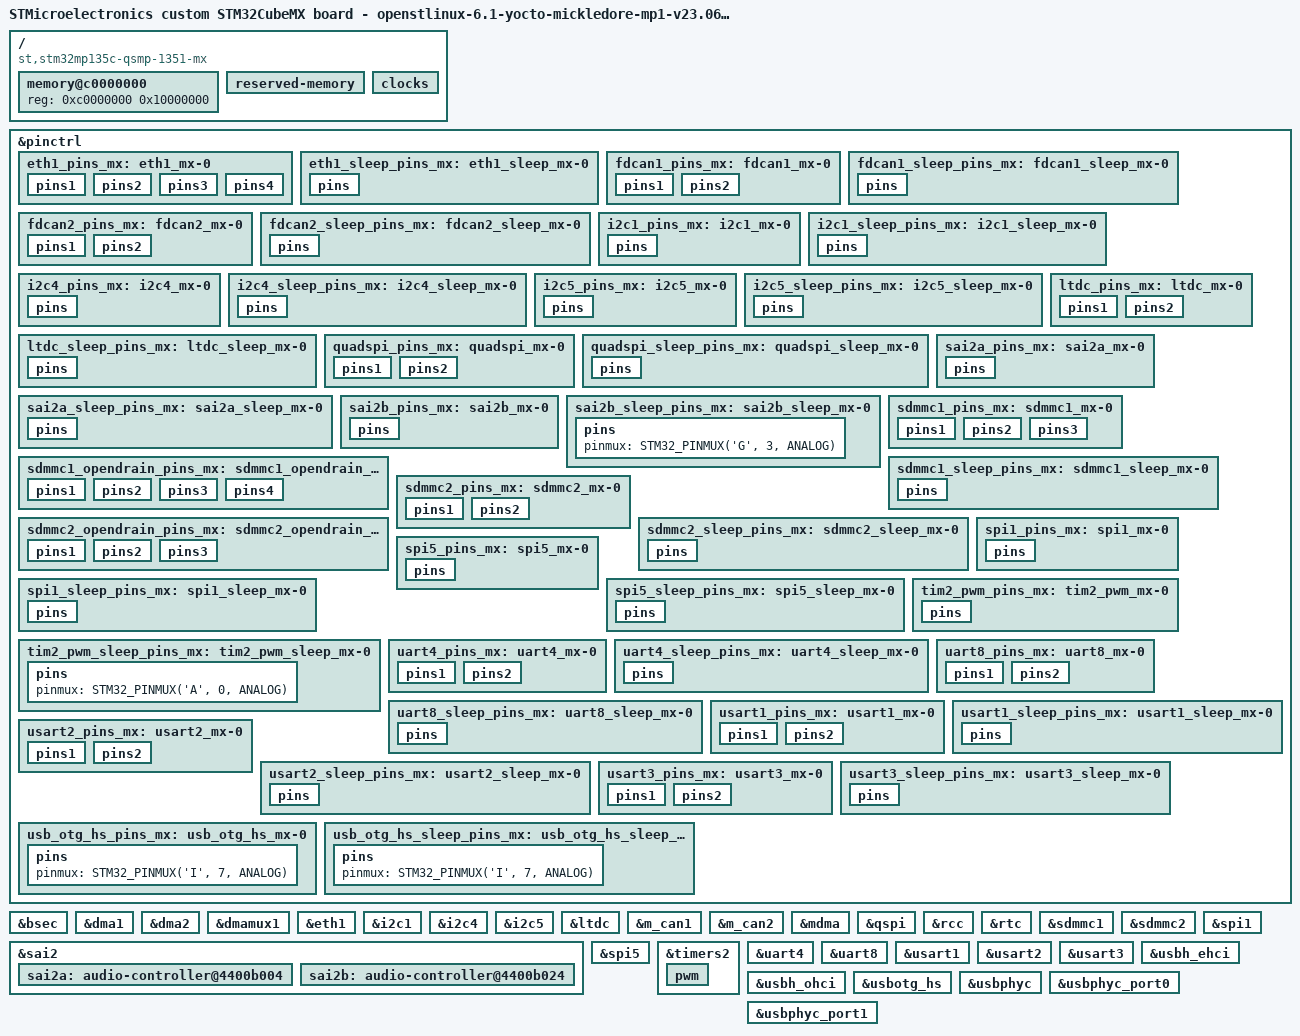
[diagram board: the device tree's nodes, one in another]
// SPDX-License-Identifier: (GPL-2.0-or-later OR BSD-3-Clause)
/*
 * Copyright (C) 2024, STMicroelectronics - All Rights Reserved
 * Author: STM32CubeMX code generation for STMicroelectronics.
 */

/* For more information on Device Tree configuration, please refer to
 * https://wiki.st.com/stm32mpu/wiki/Category:Device_tree_configuration
 */

/dts-v1/;
#include <dt-bindings/pinctrl/stm32-pinfunc.h>

#include "stm32mp135.dtsi"
#include "stm32mp13xc.dtsi"

/* USER CODE BEGIN includes */
/* USER CODE END includes */

/ {
	model = "STMicroelectronics custom STM32CubeMX board - openstlinux-6.1-yocto-mickledore-mp1-v23.06.21";
	compatible = "st,stm32mp135c-qsmp-1351-mx", "st,stm32mp135";

	memory@c0000000 {
		device_type = "memory";
		reg = <0xc0000000 0x10000000>;

		/* USER CODE BEGIN memory */
		/* USER CODE END memory */
	};

	reserved-memory {
		#address-cells = <1>;
		#size-cells = <1>;
		ranges;

		/* USER CODE BEGIN reserved-memory */
		/* USER CODE END reserved-memory */
	};

	/* USER CODE BEGIN root */
	/* USER CODE END root */

	clocks{

		/* USER CODE BEGIN clocks */
		/* USER CODE END clocks */
	};

}; /*root*/

&pinctrl {

	eth1_pins_mx: eth1_mx-0 {
		pins1 {
			pinmux = <STM32_PINMUX('A', 2, AF11)>; /* ETH1_MDIO */
			bias-disable;
			drive-push-pull;
			slew-rate = <0>;
		};
		pins2 {
			pinmux = <STM32_PINMUX('A', 7, AF11)>, /* ETH1_RX_CTL */
					 <STM32_PINMUX('B', 0, AF11)>, /* ETH1_RXD2 */
					 <STM32_PINMUX('B', 1, AF11)>, /* ETH1_RXD3 */
					 <STM32_PINMUX('C', 4, AF11)>, /* ETH1_RXD0 */
					 <STM32_PINMUX('C', 5, AF11)>, /* ETH1_RXD1 */
					 <STM32_PINMUX('D', 7, AF10)>; /* ETH1_RX_CLK */
			bias-disable;
		};
		pins3 {
			pinmux = <STM32_PINMUX('B', 11, AF11)>, /* ETH1_TX_CTL */
					 <STM32_PINMUX('C', 1, AF11)>, /* ETH1_GTX_CLK */
					 <STM32_PINMUX('C', 2, AF11)>, /* ETH1_TXD2 */
					 <STM32_PINMUX('E', 5, AF10)>, /* ETH1_TXD3 */
					 <STM32_PINMUX('F', 12, AF11)>, /* ETH1_CLK125 */
					 <STM32_PINMUX('G', 2, AF11)>, /* ETH1_MDC */
					 <STM32_PINMUX('G', 13, AF11)>, /* ETH1_TXD0 */
					 <STM32_PINMUX('G', 14, AF11)>; /* ETH1_TXD1 */
			bias-disable;
			drive-push-pull;
			slew-rate = <2>;
		};
		pins4 {
			pinmux = <STM32_PINMUX('H', 6, AF10)>; /* ETH1_PHY_INTN */
			bias-pull-up;
		};
	};

	eth1_sleep_pins_mx: eth1_sleep_mx-0 {
		pins {
			pinmux = <STM32_PINMUX('A', 2, ANALOG)>, /* ETH1_MDIO */
					 <STM32_PINMUX('A', 7, ANALOG)>, /* ETH1_RX_CTL */
					 <STM32_PINMUX('B', 0, ANALOG)>, /* ETH1_RXD2 */
					 <STM32_PINMUX('B', 1, ANALOG)>, /* ETH1_RXD3 */
					 <STM32_PINMUX('B', 11, ANALOG)>, /* ETH1_TX_CTL */
					 <STM32_PINMUX('C', 1, ANALOG)>, /* ETH1_GTX_CLK */
					 <STM32_PINMUX('C', 2, ANALOG)>, /* ETH1_TXD2 */
					 <STM32_PINMUX('C', 4, ANALOG)>, /* ETH1_RXD0 */
					 <STM32_PINMUX('C', 5, ANALOG)>, /* ETH1_RXD1 */
					 <STM32_PINMUX('D', 7, ANALOG)>, /* ETH1_RX_CLK */
					 <STM32_PINMUX('E', 5, ANALOG)>, /* ETH1_TXD3 */
					 <STM32_PINMUX('F', 12, ANALOG)>, /* ETH1_CLK125 */
					 <STM32_PINMUX('G', 2, ANALOG)>, /* ETH1_MDC */
					 <STM32_PINMUX('G', 13, ANALOG)>, /* ETH1_TXD0 */
					 <STM32_PINMUX('G', 14, ANALOG)>, /* ETH1_TXD1 */
					 <STM32_PINMUX('H', 6, ANALOG)>; /* ETH1_PHY_INTN */
		};
	};

	fdcan1_pins_mx: fdcan1_mx-0 {
		pins1 {
			pinmux = <STM32_PINMUX('D', 0, AF9)>; /* FDCAN1_RX */
			bias-disable;
		};
		pins2 {
			pinmux = <STM32_PINMUX('E', 10, AF9)>; /* FDCAN1_TX */
			bias-disable;
			drive-push-pull;
			slew-rate = <0>;
		};
	};

	fdcan1_sleep_pins_mx: fdcan1_sleep_mx-0 {
		pins {
			pinmux = <STM32_PINMUX('D', 0, ANALOG)>, /* FDCAN1_RX */
					 <STM32_PINMUX('E', 10, ANALOG)>; /* FDCAN1_TX */
		};
	};

	fdcan2_pins_mx: fdcan2_mx-0 {
		pins1 {
			pinmux = <STM32_PINMUX('B', 13, AF9)>; /* FDCAN2_TX */
			bias-disable;
			drive-push-pull;
			slew-rate = <0>;
		};
		pins2 {
			pinmux = <STM32_PINMUX('E', 0, AF9)>; /* FDCAN2_RX */
			bias-disable;
		};
	};

	fdcan2_sleep_pins_mx: fdcan2_sleep_mx-0 {
		pins {
			pinmux = <STM32_PINMUX('B', 13, ANALOG)>, /* FDCAN2_TX */
					 <STM32_PINMUX('E', 0, ANALOG)>; /* FDCAN2_RX */
		};
	};

	i2c1_pins_mx: i2c1_mx-0 {
		pins {
			pinmux = <STM32_PINMUX('D', 12, AF5)>, /* I2C1_SCL */
					 <STM32_PINMUX('E', 8, AF5)>; /* I2C1_SDA */
			bias-disable;
			drive-open-drain;
			slew-rate = <0>;
		};
	};

	i2c1_sleep_pins_mx: i2c1_sleep_mx-0 {
		pins {
			pinmux = <STM32_PINMUX('D', 12, ANALOG)>, /* I2C1_SCL */
					 <STM32_PINMUX('E', 8, ANALOG)>; /* I2C1_SDA */
		};
	};

	i2c4_pins_mx: i2c4_mx-0 {
		pins {
			pinmux = <STM32_PINMUX('B', 7, AF6)>, /* I2C4_SDA */
					 <STM32_PINMUX('E', 2, AF4)>; /* I2C4_SCL */
			bias-disable;
			drive-open-drain;
			slew-rate = <0>;
		};
	};

	i2c4_sleep_pins_mx: i2c4_sleep_mx-0 {
		pins {
			pinmux = <STM32_PINMUX('B', 7, ANALOG)>, /* I2C4_SDA */
					 <STM32_PINMUX('E', 2, ANALOG)>; /* I2C4_SCL */
		};
	};

	i2c5_pins_mx: i2c5_mx-0 {
		pins {
			pinmux = <STM32_PINMUX('D', 1, AF4)>, /* I2C5_SCL */
					 <STM32_PINMUX('E', 13, AF4)>; /* I2C5_SDA */
			bias-disable;
			drive-open-drain;
			slew-rate = <0>;
		};
	};

	i2c5_sleep_pins_mx: i2c5_sleep_mx-0 {
		pins {
			pinmux = <STM32_PINMUX('D', 1, ANALOG)>, /* I2C5_SCL */
					 <STM32_PINMUX('E', 13, ANALOG)>; /* I2C5_SDA */
		};
	};

	ltdc_pins_mx: ltdc_mx-0 {
		pins1 {
			pinmux = <STM32_PINMUX('A', 9, AF14)>, /* LTDC_R6 */
					 <STM32_PINMUX('A', 15, AF11)>, /* LTDC_G7 */
					 <STM32_PINMUX('B', 5, AF14)>, /* LTDC_DE */
					 <STM32_PINMUX('B', 6, AF7)>, /* LTDC_B6 */
					 <STM32_PINMUX('B', 10, AF14)>, /* LTDC_R3 */
					 <STM32_PINMUX('B', 12, AF14)>, /* LTDC_VSYNC */
					 <STM32_PINMUX('D', 5, AF13)>, /* LTDC_B0 */
					 <STM32_PINMUX('D', 10, AF14)>, /* LTDC_B2 */
					 <STM32_PINMUX('D', 11, AF11)>, /* LTDC_R7 */
					 <STM32_PINMUX('D', 14, AF14)>, /* LTDC_R4 */
					 <STM32_PINMUX('D', 15, AF14)>, /* LTDC_B5 */
					 <STM32_PINMUX('E', 7, AF14)>, /* LTDC_R5 */
					 <STM32_PINMUX('E', 11, AF9)>, /* LTDC_R0 */
					 <STM32_PINMUX('E', 12, AF14)>, /* LTDC_G6 */
					 <STM32_PINMUX('E', 15, AF14)>, /* LTDC_B7 */
					 <STM32_PINMUX('F', 1, AF14)>, /* LTDC_G1 */
					 <STM32_PINMUX('F', 2, AF14)>, /* LTDC_B3 */
					 <STM32_PINMUX('F', 3, AF14)>, /* LTDC_G3 */
					 <STM32_PINMUX('F', 5, AF9)>, /* LTDC_G0 */
					 <STM32_PINMUX('G', 0, AF14)>, /* LTDC_G5 */
					 <STM32_PINMUX('G', 5, AF11)>, /* LTDC_G4 */
					 <STM32_PINMUX('G', 7, AF11)>, /* LTDC_R1 */
					 <STM32_PINMUX('G', 8, AF7)>, /* LTDC_B1 */
					 <STM32_PINMUX('H', 8, AF14)>, /* LTDC_R2 */
					 <STM32_PINMUX('H', 10, AF13)>, /* LTDC_HSYNC */
					 <STM32_PINMUX('H', 13, AF14)>, /* LTDC_G2 */
					 <STM32_PINMUX('H', 14, AF11)>; /* LTDC_B4 */
			bias-disable;
			drive-push-pull;
			slew-rate = <0>;
		};
		pins2 {
			pinmux = <STM32_PINMUX('D', 9, AF13)>; /* LTDC_CLK */
			bias-disable;
			drive-push-pull;
			slew-rate = <1>;
		};
	};

	ltdc_sleep_pins_mx: ltdc_sleep_mx-0 {
		pins {
			pinmux = <STM32_PINMUX('A', 9, ANALOG)>, /* LTDC_R6 */
					 <STM32_PINMUX('A', 15, ANALOG)>, /* LTDC_G7 */
					 <STM32_PINMUX('B', 5, ANALOG)>, /* LTDC_DE */
					 <STM32_PINMUX('B', 6, ANALOG)>, /* LTDC_B6 */
					 <STM32_PINMUX('B', 10, ANALOG)>, /* LTDC_R3 */
					 <STM32_PINMUX('B', 12, ANALOG)>, /* LTDC_VSYNC */
					 <STM32_PINMUX('D', 5, ANALOG)>, /* LTDC_B0 */
					 <STM32_PINMUX('D', 9, ANALOG)>, /* LTDC_CLK */
					 <STM32_PINMUX('D', 10, ANALOG)>, /* LTDC_B2 */
					 <STM32_PINMUX('D', 11, ANALOG)>, /* LTDC_R7 */
					 <STM32_PINMUX('D', 14, ANALOG)>, /* LTDC_R4 */
					 <STM32_PINMUX('D', 15, ANALOG)>, /* LTDC_B5 */
					 <STM32_PINMUX('E', 7, ANALOG)>, /* LTDC_R5 */
					 <STM32_PINMUX('E', 11, ANALOG)>, /* LTDC_R0 */
					 <STM32_PINMUX('E', 12, ANALOG)>, /* LTDC_G6 */
					 <STM32_PINMUX('E', 15, ANALOG)>, /* LTDC_B7 */
					 <STM32_PINMUX('F', 1, ANALOG)>, /* LTDC_G1 */
					 <STM32_PINMUX('F', 2, ANALOG)>, /* LTDC_B3 */
					 <STM32_PINMUX('F', 3, ANALOG)>, /* LTDC_G3 */
					 <STM32_PINMUX('F', 5, ANALOG)>, /* LTDC_G0 */
					 <STM32_PINMUX('G', 0, ANALOG)>, /* LTDC_G5 */
					 <STM32_PINMUX('G', 5, ANALOG)>, /* LTDC_G4 */
					 <STM32_PINMUX('G', 7, ANALOG)>, /* LTDC_R1 */
					 <STM32_PINMUX('G', 8, ANALOG)>, /* LTDC_B1 */
					 <STM32_PINMUX('H', 8, ANALOG)>, /* LTDC_R2 */
					 <STM32_PINMUX('H', 10, ANALOG)>, /* LTDC_HSYNC */
					 <STM32_PINMUX('H', 13, ANALOG)>, /* LTDC_G2 */
					 <STM32_PINMUX('H', 14, ANALOG)>; /* LTDC_B4 */
		};
	};

	quadspi_pins_mx: quadspi_mx-0 {
		pins1 {
			pinmux = <STM32_PINMUX('B', 2, AF9)>, /* QUADSPI_BK1_NCS */
					 <STM32_PINMUX('E', 9, AF9)>, /* QUADSPI_BK1_IO1 */
					 <STM32_PINMUX('F', 8, AF10)>; /* QUADSPI_BK1_IO0 */
			bias-disable;
			drive-push-pull;
			slew-rate = <1>;
		};
		pins2 {
			pinmux = <STM32_PINMUX('F', 10, AF9)>; /* QUADSPI_CLK */
			bias-disable;
			drive-push-pull;
			slew-rate = <2>;
		};
	};

	quadspi_sleep_pins_mx: quadspi_sleep_mx-0 {
		pins {
			pinmux = <STM32_PINMUX('B', 2, ANALOG)>, /* QUADSPI_BK1_NCS */
					 <STM32_PINMUX('E', 9, ANALOG)>, /* QUADSPI_BK1_IO1 */
					 <STM32_PINMUX('F', 8, ANALOG)>, /* QUADSPI_BK1_IO0 */
					 <STM32_PINMUX('F', 10, ANALOG)>; /* QUADSPI_CLK */
		};
	};

	sai2a_pins_mx: sai2a_mx-0 {
		pins {
			pinmux = <STM32_PINMUX('G', 1, AF3)>, /* SAI2_FS_A */
					 <STM32_PINMUX('G', 12, AF4)>, /* SAI2_SCK_A */
					 <STM32_PINMUX('H', 11, AF3)>; /* SAI2_SD_A */
			bias-disable;
			drive-push-pull;
			slew-rate = <0>;
		};
	};

	sai2a_sleep_pins_mx: sai2a_sleep_mx-0 {
		pins {
			pinmux = <STM32_PINMUX('G', 1, ANALOG)>, /* SAI2_FS_A */
					 <STM32_PINMUX('G', 12, ANALOG)>, /* SAI2_SCK_A */
					 <STM32_PINMUX('H', 11, ANALOG)>; /* SAI2_SD_A */
		};
	};

	sai2b_pins_mx: sai2b_mx-0 {
		pins {
			pinmux = <STM32_PINMUX('G', 3, AF6)>; /* SAI2_SD_B */
			bias-disable;
			drive-push-pull;
			slew-rate = <0>;
		};
	};

	sai2b_sleep_pins_mx: sai2b_sleep_mx-0 {
		pins {
			pinmux = <STM32_PINMUX('G', 3, ANALOG)>; /* SAI2_SD_B */
		};
	};

	sdmmc1_pins_mx: sdmmc1_mx-0 {
		pins1 {
			pinmux = <STM32_PINMUX('C', 9, AF12)>, /* SDMMC1_D1 */
					 <STM32_PINMUX('C', 10, AF12)>, /* SDMMC1_D2 */
					 <STM32_PINMUX('C', 11, AF12)>; /* SDMMC1_D3 */
			bias-disable;
			drive-push-pull;
			slew-rate = <1>;
		};
		pins2 {
			pinmux = <STM32_PINMUX('C', 12, AF12)>; /* SDMMC1_CK */
			bias-disable;
			drive-push-pull;
			slew-rate = <3>;
		};
		pins3 {
			pinmux = <STM32_PINMUX('C', 8, AF12)>, /* SDMMC1_D0 */
					 <STM32_PINMUX('D', 2, AF12)>; /* SDMMC1_CMD */
			bias-pull-up;
			drive-push-pull;
			slew-rate = <1>;
		};
	};

	sdmmc1_opendrain_pins_mx: sdmmc1_opendrain_mx-0 {
		pins1 {
			pinmux = <STM32_PINMUX('C', 9, AF12)>, /* SDMMC1_D1 */
					 <STM32_PINMUX('C', 10, AF12)>, /* SDMMC1_D2 */
					 <STM32_PINMUX('C', 11, AF12)>; /* SDMMC1_D3 */
			bias-disable;
			drive-push-pull;
			slew-rate = <1>;
		};
		pins2 {
			pinmux = <STM32_PINMUX('C', 12, AF12)>; /* SDMMC1_CK */
			bias-disable;
			drive-push-pull;
			slew-rate = <3>;
		};
		pins3 {
			pinmux = <STM32_PINMUX('C', 8, AF12)>; /* SDMMC1_D0 */
			bias-pull-up;
			drive-push-pull;
			slew-rate = <1>;
		};
		pins4 {
			pinmux = <STM32_PINMUX('D', 2, AF12)>; /* SDMMC1_CMD */
			bias-pull-up;
			drive-open-drain;
			slew-rate = <1>;
		};
	};

	sdmmc1_sleep_pins_mx: sdmmc1_sleep_mx-0 {
		pins {
			pinmux = <STM32_PINMUX('C', 8, ANALOG)>, /* SDMMC1_D0 */
					 <STM32_PINMUX('C', 9, ANALOG)>, /* SDMMC1_D1 */
					 <STM32_PINMUX('C', 10, ANALOG)>, /* SDMMC1_D2 */
					 <STM32_PINMUX('C', 11, ANALOG)>, /* SDMMC1_D3 */
					 <STM32_PINMUX('C', 12, ANALOG)>, /* SDMMC1_CK */
					 <STM32_PINMUX('D', 2, ANALOG)>; /* SDMMC1_CMD */
		};
	};

	sdmmc2_pins_mx: sdmmc2_mx-0 {
		pins1 {
			pinmux = <STM32_PINMUX('B', 3, AF10)>, /* SDMMC2_D2 */
					 <STM32_PINMUX('B', 4, AF10)>, /* SDMMC2_D3 */
					 <STM32_PINMUX('B', 9, AF10)>, /* SDMMC2_D5 */
					 <STM32_PINMUX('B', 14, AF10)>, /* SDMMC2_D0 */
					 <STM32_PINMUX('B', 15, AF10)>, /* SDMMC2_D1 */
					 <STM32_PINMUX('C', 6, AF10)>, /* SDMMC2_D6 */
					 <STM32_PINMUX('C', 7, AF10)>, /* SDMMC2_D7 */
					 <STM32_PINMUX('F', 0, AF10)>, /* SDMMC2_D4 */
					 <STM32_PINMUX('G', 6, AF10)>; /* SDMMC2_CMD */
			bias-disable;
			drive-push-pull;
			slew-rate = <1>;
		};
		pins2 {
			pinmux = <STM32_PINMUX('E', 3, AF10)>; /* SDMMC2_CK */
			bias-disable;
			drive-push-pull;
			slew-rate = <3>;
		};
	};

	sdmmc2_opendrain_pins_mx: sdmmc2_opendrain_mx-0 {
		pins1 {
			pinmux = <STM32_PINMUX('B', 3, AF10)>, /* SDMMC2_D2 */
					 <STM32_PINMUX('B', 4, AF10)>, /* SDMMC2_D3 */
					 <STM32_PINMUX('B', 9, AF10)>, /* SDMMC2_D5 */
					 <STM32_PINMUX('B', 14, AF10)>, /* SDMMC2_D0 */
					 <STM32_PINMUX('B', 15, AF10)>, /* SDMMC2_D1 */
					 <STM32_PINMUX('C', 6, AF10)>, /* SDMMC2_D6 */
					 <STM32_PINMUX('C', 7, AF10)>, /* SDMMC2_D7 */
					 <STM32_PINMUX('F', 0, AF10)>; /* SDMMC2_D4 */
			bias-disable;
			drive-push-pull;
			slew-rate = <1>;
		};
		pins2 {
			pinmux = <STM32_PINMUX('E', 3, AF10)>; /* SDMMC2_CK */
			bias-disable;
			drive-push-pull;
			slew-rate = <3>;
		};
		pins3 {
			pinmux = <STM32_PINMUX('G', 6, AF10)>; /* SDMMC2_CMD */
			bias-disable;
			drive-open-drain;
			slew-rate = <1>;
		};
	};

	sdmmc2_sleep_pins_mx: sdmmc2_sleep_mx-0 {
		pins {
			pinmux = <STM32_PINMUX('B', 3, ANALOG)>, /* SDMMC2_D2 */
					 <STM32_PINMUX('B', 4, ANALOG)>, /* SDMMC2_D3 */
					 <STM32_PINMUX('B', 9, ANALOG)>, /* SDMMC2_D5 */
					 <STM32_PINMUX('B', 14, ANALOG)>, /* SDMMC2_D0 */
					 <STM32_PINMUX('B', 15, ANALOG)>, /* SDMMC2_D1 */
					 <STM32_PINMUX('C', 6, ANALOG)>, /* SDMMC2_D6 */
					 <STM32_PINMUX('C', 7, ANALOG)>, /* SDMMC2_D7 */
					 <STM32_PINMUX('E', 3, ANALOG)>, /* SDMMC2_CK */
					 <STM32_PINMUX('F', 0, ANALOG)>, /* SDMMC2_D4 */
					 <STM32_PINMUX('G', 6, ANALOG)>; /* SDMMC2_CMD */
		};
	};

	spi1_pins_mx: spi1_mx-0 {
		pins {
			pinmux = <STM32_PINMUX('A', 3, AF5)>, /* SPI1_MOSI */
					 <STM32_PINMUX('A', 5, AF5)>, /* SPI1_NSS */
					 <STM32_PINMUX('A', 6, AF5)>, /* SPI1_MISO */
					 <STM32_PINMUX('C', 3, AF6)>; /* SPI1_SCK */
			bias-disable;
			drive-push-pull;
			slew-rate = <1>;
		};
	};

	spi1_sleep_pins_mx: spi1_sleep_mx-0 {
		pins {
			pinmux = <STM32_PINMUX('A', 3, ANALOG)>, /* SPI1_MOSI */
					 <STM32_PINMUX('A', 5, ANALOG)>, /* SPI1_NSS */
					 <STM32_PINMUX('A', 6, ANALOG)>, /* SPI1_MISO */
					 <STM32_PINMUX('C', 3, ANALOG)>; /* SPI1_SCK */
		};
	};

	spi5_pins_mx: spi5_mx-0 {
		pins {
			pinmux = <STM32_PINMUX('E', 4, AF1)>, /* SPI5_MISO */
					 <STM32_PINMUX('F', 6, AF5)>, /* SPI5_NSS */
					 <STM32_PINMUX('G', 10, AF5)>, /* SPI5_SCK */
					 <STM32_PINMUX('H', 12, AF5)>; /* SPI5_MOSI */
			bias-disable;
			drive-push-pull;
			slew-rate = <1>;
		};
	};

	spi5_sleep_pins_mx: spi5_sleep_mx-0 {
		pins {
			pinmux = <STM32_PINMUX('E', 4, ANALOG)>, /* SPI5_MISO */
					 <STM32_PINMUX('F', 6, ANALOG)>, /* SPI5_NSS */
					 <STM32_PINMUX('G', 10, ANALOG)>, /* SPI5_SCK */
					 <STM32_PINMUX('H', 12, ANALOG)>; /* SPI5_MOSI */
		};
	};

	tim2_pwm_pins_mx: tim2_pwm_mx-0 {
		pins {
			pinmux = <STM32_PINMUX('A', 0, AF1)>; /* TIM2_CH1 */
			bias-disable;
			drive-push-pull;
			slew-rate = <0>;
		};
	};

	tim2_pwm_sleep_pins_mx: tim2_pwm_sleep_mx-0 {
		pins {
			pinmux = <STM32_PINMUX('A', 0, ANALOG)>; /* TIM2_CH1 */
		};
	};

	uart4_pins_mx: uart4_mx-0 {
		pins1 {
			pinmux = <STM32_PINMUX('D', 6, AF8)>; /* UART4_TX */
			bias-disable;
			drive-push-pull;
			slew-rate = <0>;
		};
		pins2 {
			pinmux = <STM32_PINMUX('D', 8, AF8)>; /* UART4_RX */
			bias-disable;
		};
	};

	uart4_sleep_pins_mx: uart4_sleep_mx-0 {
		pins {
			pinmux = <STM32_PINMUX('D', 6, ANALOG)>, /* UART4_TX */
					 <STM32_PINMUX('D', 8, ANALOG)>; /* UART4_RX */
		};
	};

	uart8_pins_mx: uart8_mx-0 {
		pins1 {
			pinmux = <STM32_PINMUX('E', 1, AF8)>, /* UART8_TX */
					 <STM32_PINMUX('E', 14, AF8)>; /* UART8_DE */
			bias-disable;
			drive-push-pull;
			slew-rate = <0>;
		};
		pins2 {
			pinmux = <STM32_PINMUX('F', 9, AF8)>; /* UART8_RX */
			bias-disable;
		};
	};

	uart8_sleep_pins_mx: uart8_sleep_mx-0 {
		pins {
			pinmux = <STM32_PINMUX('E', 1, ANALOG)>, /* UART8_TX */
					 <STM32_PINMUX('E', 14, ANALOG)>, /* UART8_DE */
					 <STM32_PINMUX('F', 9, ANALOG)>; /* UART8_RX */
		};
	};

	usart1_pins_mx: usart1_mx-0 {
		pins1 {
			pinmux = <STM32_PINMUX('A', 12, AF7)>, /* USART1_DE */
					 <STM32_PINMUX('C', 0, AF7)>; /* USART1_TX */
			bias-disable;
			drive-push-pull;
			slew-rate = <0>;
		};
		pins2 {
			pinmux = <STM32_PINMUX('D', 13, AF7)>; /* USART1_RX */
			bias-disable;
		};
	};

	usart1_sleep_pins_mx: usart1_sleep_mx-0 {
		pins {
			pinmux = <STM32_PINMUX('A', 12, ANALOG)>, /* USART1_DE */
					 <STM32_PINMUX('C', 0, ANALOG)>, /* USART1_TX */
					 <STM32_PINMUX('D', 13, ANALOG)>; /* USART1_RX */
		};
	};

	usart2_pins_mx: usart2_mx-0 {
		pins1 {
			pinmux = <STM32_PINMUX('D', 3, AF3)>, /* USART2_CTS */
					 <STM32_PINMUX('F', 4, AF3)>; /* USART2_RX */
			bias-disable;
		};
		pins2 {
			pinmux = <STM32_PINMUX('D', 4, AF3)>, /* USART2_RTS */
					 <STM32_PINMUX('F', 13, AF7)>; /* USART2_TX */
			bias-disable;
			drive-push-pull;
			slew-rate = <0>;
		};
	};

	usart2_sleep_pins_mx: usart2_sleep_mx-0 {
		pins {
			pinmux = <STM32_PINMUX('D', 3, ANALOG)>, /* USART2_CTS */
					 <STM32_PINMUX('D', 4, ANALOG)>, /* USART2_RTS */
					 <STM32_PINMUX('F', 4, ANALOG)>, /* USART2_RX */
					 <STM32_PINMUX('F', 13, ANALOG)>; /* USART2_TX */
		};
	};

	usart3_pins_mx: usart3_mx-0 {
		pins1 {
			pinmux = <STM32_PINMUX('G', 11, AF7)>; /* USART3_TX */
			bias-disable;
			drive-push-pull;
			slew-rate = <0>;
		};
		pins2 {
			pinmux = <STM32_PINMUX('G', 4, AF8)>; /* USART3_RX */
			bias-disable;
		};
	};

	usart3_sleep_pins_mx: usart3_sleep_mx-0 {
		pins {
			pinmux = <STM32_PINMUX('G', 4, ANALOG)>, /* USART3_RX */
					 <STM32_PINMUX('G', 11, ANALOG)>; /* USART3_TX */
		};
	};

	usb_otg_hs_pins_mx: usb_otg_hs_mx-0 {
		pins {
			pinmux = <STM32_PINMUX('I', 7, ANALOG)>; /* USB_OTG_HS_VBUS */
		};
	};

	usb_otg_hs_sleep_pins_mx: usb_otg_hs_sleep_mx-0 {
		pins {
			pinmux = <STM32_PINMUX('I', 7, ANALOG)>; /* USB_OTG_HS_VBUS */
		};
	};

	/* USER CODE BEGIN pinctrl */
	/* USER CODE END pinctrl */
};

&bsec{
	status = "okay";

	/* USER CODE BEGIN bsec */
	/* USER CODE END bsec */
};

&dma1{
	status = "okay";

	/* USER CODE BEGIN dma1 */
	/* USER CODE END dma1 */
};

&dma2{
	status = "okay";

	/* USER CODE BEGIN dma2 */
	/* USER CODE END dma2 */
};

&dmamux1{
	status = "okay";

	dma-masters = <&dma1 &dma2>;
	dma-channels = <16>;

	/* USER CODE BEGIN dmamux1 */
	/* USER CODE END dmamux1 */
};

&eth1{
	pinctrl-names = "default", "sleep";
	pinctrl-0 = <&eth1_pins_mx>;
	pinctrl-1 = <&eth1_sleep_pins_mx>;
	status = "okay";

	/* USER CODE BEGIN eth1 */
	/* USER CODE END eth1 */
};

&i2c1{
	pinctrl-names = "default", "sleep";
	pinctrl-0 = <&i2c1_pins_mx>;
	pinctrl-1 = <&i2c1_sleep_pins_mx>;
	status = "okay";

	/* USER CODE BEGIN i2c1 */
	/* USER CODE END i2c1 */
};

&i2c4{
	pinctrl-names = "default", "sleep";
	pinctrl-0 = <&i2c4_pins_mx>;
	pinctrl-1 = <&i2c4_sleep_pins_mx>;
	status = "okay";

	/* USER CODE BEGIN i2c4 */
	/* USER CODE END i2c4 */
};

&i2c5{
	pinctrl-names = "default", "sleep";
	pinctrl-0 = <&i2c5_pins_mx>;
	pinctrl-1 = <&i2c5_sleep_pins_mx>;
	status = "okay";

	/* USER CODE BEGIN i2c5 */
	/* USER CODE END i2c5 */
};

&ltdc{
	pinctrl-names = "default", "sleep";
	pinctrl-0 = <&ltdc_pins_mx>;
	pinctrl-1 = <&ltdc_sleep_pins_mx>;
	status = "okay";

	/* USER CODE BEGIN ltdc */
	/* USER CODE END ltdc */
};

&m_can1{
	pinctrl-names = "default", "sleep";
	pinctrl-0 = <&fdcan1_pins_mx>;
	pinctrl-1 = <&fdcan1_sleep_pins_mx>;
	status = "okay";

	/* USER CODE BEGIN m_can1 */
	/* USER CODE END m_can1 */
};

&m_can2{
	pinctrl-names = "default", "sleep";
	pinctrl-0 = <&fdcan2_pins_mx>;
	pinctrl-1 = <&fdcan2_sleep_pins_mx>;
	status = "okay";

	/* USER CODE BEGIN m_can2 */
	/* USER CODE END m_can2 */
};

&mdma{
	status = "okay";

	/* USER CODE BEGIN mdma */
	/* USER CODE END mdma */
};

&qspi{
	pinctrl-names = "default", "sleep";
	pinctrl-0 = <&quadspi_pins_mx>;
	pinctrl-1 = <&quadspi_sleep_pins_mx>;
	status = "okay";

	/* USER CODE BEGIN qspi */
	/* USER CODE END qspi */
};

&rcc{
	status = "okay";

	/* USER CODE BEGIN rcc */
	/* USER CODE END rcc */
};

&rtc{
	status = "okay";

	/* USER CODE BEGIN rtc */
	/* USER CODE END rtc */
};

&sai2{
	pinctrl-names = "default", "sleep";
	pinctrl-0 = <&sai2a_pins_mx>, <&sai2b_pins_mx>;
	pinctrl-1 = <&sai2a_sleep_pins_mx>, <&sai2b_sleep_pins_mx>;
	status = "okay";

	/* USER CODE BEGIN sai2 */
	/* USER CODE END sai2 */

	sai2a:audio-controller@4400b004{
		status = "okay";

		/* USER CODE BEGIN sai2a */
		/* USER CODE END sai2a */
	};

	sai2b:audio-controller@4400b024{
		status = "okay";

		/* USER CODE BEGIN sai2b */
		/* USER CODE END sai2b */
	};
};

&sdmmc1{
	pinctrl-names = "default", "opendrain", "sleep";
	pinctrl-0 = <&sdmmc1_pins_mx>;
	pinctrl-1 = <&sdmmc1_opendrain_pins_mx>;
	pinctrl-2 = <&sdmmc1_sleep_pins_mx>;
	status = "okay";

	/* USER CODE BEGIN sdmmc1 */
	/* USER CODE END sdmmc1 */
};

&sdmmc2{
	pinctrl-names = "default", "opendrain", "sleep";
	pinctrl-0 = <&sdmmc2_pins_mx>;
	pinctrl-1 = <&sdmmc2_opendrain_pins_mx>;
	pinctrl-2 = <&sdmmc2_sleep_pins_mx>;
	status = "okay";

	/* USER CODE BEGIN sdmmc2 */
	/* USER CODE END sdmmc2 */
};

&spi1{
	pinctrl-names = "default", "sleep";
	pinctrl-0 = <&spi1_pins_mx>;
	pinctrl-1 = <&spi1_sleep_pins_mx>;
	status = "okay";

	/* USER CODE BEGIN spi1 */
	/* USER CODE END spi1 */
};

&spi5{
	pinctrl-names = "default", "sleep";
	pinctrl-0 = <&spi5_pins_mx>;
	pinctrl-1 = <&spi5_sleep_pins_mx>;
	status = "okay";

	/* USER CODE BEGIN spi5 */
	/* USER CODE END spi5 */
};

&timers2{
	status = "okay";

	/* USER CODE BEGIN timers2 */
	/* USER CODE END timers2 */

	pwm{
		pinctrl-names = "default", "sleep";
		pinctrl-0 = <&tim2_pwm_pins_mx>;
		pinctrl-1 = <&tim2_pwm_sleep_pins_mx>;
		status = "okay";

		/* USER CODE BEGIN timers2_pwm */
		/* USER CODE END timers2_pwm */
	};
};

&uart4{
	pinctrl-names = "default", "sleep";
	pinctrl-0 = <&uart4_pins_mx>;
	pinctrl-1 = <&uart4_sleep_pins_mx>;
	status = "okay";

	/* USER CODE BEGIN uart4 */
	/* USER CODE END uart4 */
};

&uart8{
	pinctrl-names = "default", "sleep";
	pinctrl-0 = <&uart8_pins_mx>;
	pinctrl-1 = <&uart8_sleep_pins_mx>;
	status = "okay";

	/* USER CODE BEGIN uart8 */
	/* USER CODE END uart8 */
};

&usart1{
	pinctrl-names = "default", "sleep";
	pinctrl-0 = <&usart1_pins_mx>;
	pinctrl-1 = <&usart1_sleep_pins_mx>;
	status = "okay";

	/* USER CODE BEGIN usart1 */
	/* USER CODE END usart1 */
};

&usart2{
	pinctrl-names = "default", "sleep";
	pinctrl-0 = <&usart2_pins_mx>;
	pinctrl-1 = <&usart2_sleep_pins_mx>;
	status = "okay";

	/* USER CODE BEGIN usart2 */
	/* USER CODE END usart2 */
};

&usart3{
	pinctrl-names = "default", "sleep";
	pinctrl-0 = <&usart3_pins_mx>;
	pinctrl-1 = <&usart3_sleep_pins_mx>;
	status = "okay";

	/* USER CODE BEGIN usart3 */
	/* USER CODE END usart3 */
};

&usbh_ehci{
	status = "okay";

	/* USER CODE BEGIN usbh_ehci */
	/* USER CODE END usbh_ehci */
};

&usbh_ohci{
	status = "okay";

	/* USER CODE BEGIN usbh_ohci */
	/* USER CODE END usbh_ohci */
};

&usbotg_hs{
	pinctrl-names = "default", "sleep";
	pinctrl-0 = <&usb_otg_hs_pins_mx>;
	pinctrl-1 = <&usb_otg_hs_sleep_pins_mx>;
	status = "okay";

	/* USER CODE BEGIN usbotg_hs */
	/* USER CODE END usbotg_hs */
};

&usbphyc{
	status = "okay";

	/* USER CODE BEGIN usbphyc */
	/* USER CODE END usbphyc */
};

&usbphyc_port0{
	status = "okay";

	/* USER CODE BEGIN usbphyc_port0 */
	/* USER CODE END usbphyc_port0 */
};

&usbphyc_port1{
	status = "okay";

	/* USER CODE BEGIN usbphyc_port1 */
	/* USER CODE END usbphyc_port1 */
};

/* USER CODE BEGIN addons */
/* USER CODE END addons */

